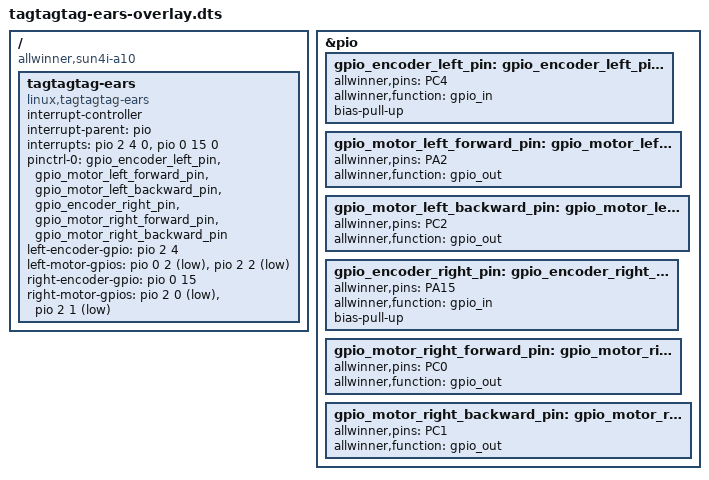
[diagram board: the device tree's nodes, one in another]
/dts-v1/;
/plugin/;

/ {
	compatible = "allwinner,sun4i-a10", "allwinner,sun7i-a20", "allwinner,sun8i-h3", "allwinner,sun50i-a64", "allwinner,sun50i-h5";

	fragment@0 {
		target = <&pio>;
		__overlay__ {
			gpio_encoder_left_pin: gpio_encoder_left_pin@1 {
				allwinner,pins = "PC4";
				allwinner,function = "gpio_in";
				bias-pull-up;
			};
			gpio_motor_left_forward_pin: gpio_motor_left_forward_pin@2 {
				allwinner,pins = "PA2";
				allwinner,function = "gpio_out";
			};
			gpio_motor_left_backward_pin: gpio_motor_left_backward_pin@3 {
				allwinner,pins = "PC2";
				allwinner,function = "gpio_out";
			};
            
			gpio_encoder_right_pin: gpio_encoder_right_pin@4 {
				allwinner,pins = "PA15";
				allwinner,function = "gpio_in";
				bias-pull-up;
			};
			gpio_motor_right_forward_pin: gpio_motor_right_forward_pin@5 {
				allwinner,pins = "PC0";
				allwinner,function = "gpio_out";
			};
			gpio_motor_right_backward_pin: gpio_motor_right_backward_pin@6 {
				allwinner,pins = "PC1";
				allwinner,function = "gpio_out";
			};
		};
	};

	fragment@1 {
		target-path = "/";
		__overlay__ {
			tagtagtag-ears {
				compatible = "linux,tagtagtag-ears";
				pinctrl-names = "default";
				interrupt-controller;
				#interrupt-cells = <2>;
				interrupt-parent = <&pio>;
				interrupts = <&pio 2 4 0 &pio 0 15 0>; /* PA10 IRQ_TYPE_EDGE_FALLING */
				pinctrl-0 = <&gpio_encoder_left_pin 
					     &gpio_motor_left_forward_pin 
					     &gpio_motor_left_backward_pin 
					     &gpio_encoder_right_pin 
					     &gpio_motor_right_forward_pin 
					     &gpio_motor_right_backward_pin>;

                left-encoder-gpio = <&pio 2 4 0>; 		        // PC4
                left-motor-gpios = <&pio 0 2 1 &pio 2 2 1>;	    // PA2, PC2
                right-encoder-gpio = <&pio 0 15 0>;		    	// PA15
                right-motor-gpios = <&pio 2 0 1 &pio 2 1 1>;	// PC0, PC1

				status = "okay";
			};
		};
	};
};
